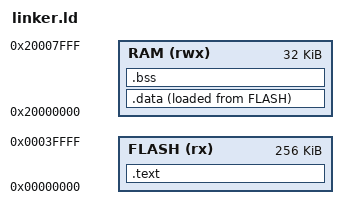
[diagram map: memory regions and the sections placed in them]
ENTRY(Reset_Handler)

MEMORY
{
  FLASH (rx) : ORIGIN = 0x00000000, LENGTH = 256K
  RAM (rwx)  : ORIGIN = 0x20000000, LENGTH = 32K
}

_estack = ORIGIN(RAM) + LENGTH(RAM);

SECTIONS
{
  .text : {
    KEEP(*(.isr_vector))
    *(.text*)
    *(.rodata*)
    *(.ARM.exidx*)
    . = ALIGN(4);
  } > FLASH

  _sidata = LOADADDR(.data);

  .data : {
    . = ALIGN(4);
    _sdata = .;
    *(.data*)
    . = ALIGN(4);
    _edata = .;
  } > RAM AT > FLASH

  __bss_start__ = .;
  .bss : {
    . = ALIGN(4);
    _sbss = .;
    *(.bss*)
    *(COMMON)
    . = ALIGN(4);
    _ebss = .;
  } > RAM
  __bss_end__ = .;

  _end = .;
}
